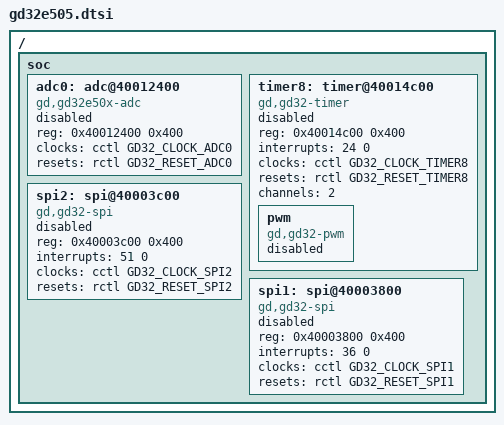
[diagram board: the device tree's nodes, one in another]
#include <arm/gd/gd32e50x/gd32e50x.dtsi>

/ {
    soc {
        adc0: adc@40012400 {
            compatible = "gd,gd32e50x-adc";
            reg = <0x40012400 0x400>;
            clocks = <&cctl GD32_CLOCK_ADC0>;
            resets = <&rctl GD32_RESET_ADC0>;
            #io-channel-cells = <1>;
            #address-cells = <1>;
            #size-cells = <0>;
            status = "disabled";
        };
    };
};

/ {
    soc {
        timer8: timer@40014c00 {
            compatible = "gd,gd32-timer";
            reg = <0x40014c00 0x400>;
            interrupts = <24 0>;
            interrupt-names = "global";
            clocks = <&cctl GD32_CLOCK_TIMER8>;
            resets = <&rctl GD32_RESET_TIMER8>;
            channels = <2>;
            status = "disabled";
            pwm {
                compatible = "gd,gd32-pwm";
                status = "disabled";
                #pwm-cells = <3>;
            };
        };
    };
};

/ {
    soc {
        spi2: spi@40003c00 {
            compatible = "gd,gd32-spi";
            reg = <0x40003c00 0x400>;
            interrupts = <51 0>;
            clocks = <&cctl GD32_CLOCK_SPI2>;
            resets = <&rctl GD32_RESET_SPI2>;
            #address-cells = <1>;
            #size-cells = <0>;
            status = "disabled";
        };
    };
};

/ {
    soc {
        spi1: spi@40003800 {
            compatible = "gd,gd32-spi";
            reg = <0x40003800 0x400>;
            interrupts = <36 0>;
            clocks = <&cctl GD32_CLOCK_SPI1>;
            resets = <&rctl GD32_RESET_SPI1>;
            #address-cells = <1>;
            #size-cells = <0>;
            status = "disabled";
        };
    };
};
